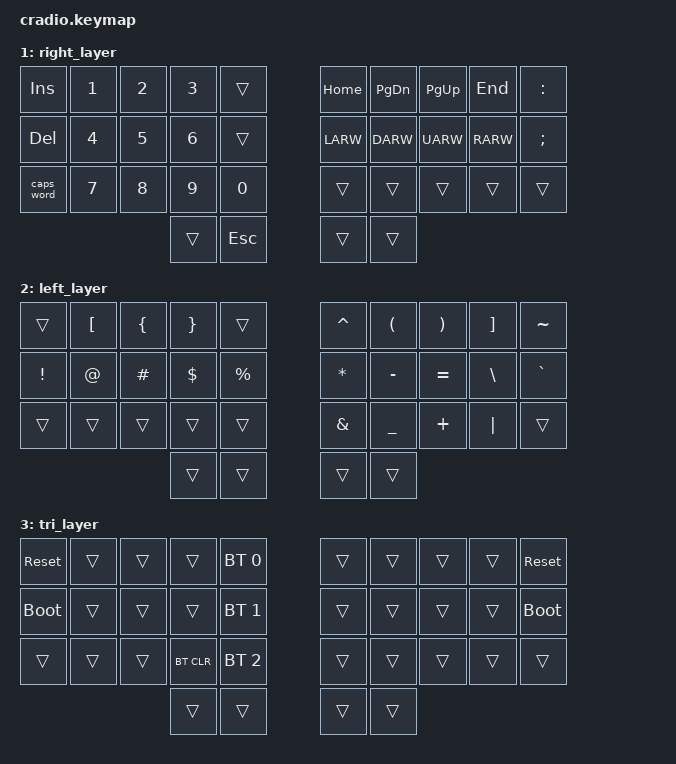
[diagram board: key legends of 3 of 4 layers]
// Copyright (c) 2022 The ZMK Contributors
// SPDX-License-Identifier: MIT

#include <behaviors.dtsi>
#include <dt-bindings/zmk/keys.h>
#include <dt-bindings/zmk/bt.h>

// Home row mods macro
#define HRML(k1,k2,k3,k4) &ht LSHFT k1  &ht LALT k2  &ht LCTRL k3  &ht LGUI k4
#define HRMR(k1,k2,k3,k4) &ht RGUI k1  &ht RCTRL k2  &ht RALT k3  &ht RSHFT k4
#include <dt-bindings/zmk/matrix_transform.h>

&default_transform {
    map = <
    RC(0,14) RC(0,1)  RC(0,2)  RC(0,3)  RC(0,4)    RC(0,21) RC(0,20) RC(0,19) RC(0,18) RC(0,31)
    RC(0,5)  RC(0,6)  RC(0,7)  RC(0,8)  RC(0,9)    RC(0,27) RC(0,26) RC(0,24) RC(0,23) RC(0,22)
    RC(0,10) RC(0,11) RC(0,12) RC(0,13) RC(0,0)    RC(0,32) RC(0,17) RC(0,30) RC(0,33) RC(0,28)
                               RC(0,16) RC(0,15)   RC(0,29) RC(0,25)
    >;
};
/ {
    behaviors {
        ht: hold_tap {
            label = "hold_tap";
            compatible = "zmk,behavior-hold-tap";
            #binding-cells = <2>;
            flavor = "tap-preferred";
            tapping-term-ms = <220>;
            quick-tap-ms = <150>;
            global-quick-tap;
            bindings = <&kp>, <&kp>;
        };
    };

    conditional_layers {
        compatible = "zmk,conditional-layers";
        tri_layer {
            if-layers = <1 2>;
            then-layer = <3>;
        };
    };

    keymap {
        compatible = "zmk,keymap";
        default_layer {
            bindings = <
        //╭──────────┬──────────┬──────────┬──────────┬──────────╮   ╭──────────┬──────────┬──────────┬──────────┬──────────╮
        //│  Q       │  W       │  E       │  R       │  T       │   │  Y       │  U       │  I       │  O       │  P       │
            &kp Q      &kp W      &kp E      &kp R      &kp T          &kp Y      &kp U      &kp I      &kp O      &kp P
        //├──────────┼──────────┼──────────┼──────────┼──────────┤   ├──────────┼──────────┼──────────┼──────────┼──────────┤
        //│  A       │  S       │  D       │  F       │  G       │   │  H       │  J       │  K       │  L       │ ' "      │
            HRML(A,        S,         D,         F)     &kp G          &kp H      HRMR(J,        K,         L,        SQT)
        //├──────────┼──────────┼──────────┼──────────┼──────────┤   ├──────────┼──────────┼──────────┼──────────┼──────────┤
        //│  Z       │  X       │  C       │  V       │  B       │   │  N       │  M       │ , <      │ . >      │ / ?      │
            &kp Z      &kp X      &kp C      &kp V      &kp B          &kp N      &kp M      &kp COMMA  &kp DOT    &kp FSLH
        //╰──────────┴──────────┴──────────┼──────────┼──────────┤   ├──────────┼──────────┼──────────┴──────────┴──────────╯
                                            &lt 2 TAB   &kp SPACE     &kp BCPC  &lt 1 ENTER
        //                                 ╰──────────┴──────────╯   ╰──────────┴──────────╯
            >;
        };

        right_layer {
            bindings = <
        //╭──────────┬──────────┬──────────┬──────────┬──────────╮   ╭──────────┬──────────┬──────────┬──────────┬──────────╮
        //│ INSERT   │  1       │  2       │  3       │          │   │ HOME     │ PAGE DN  │ PAGE UP  │ END      │  :       │
            &kp INS    &kp N1     &kp N2     &kp N3     &trans         &kp HOME   &kp PG_DN  &kp PG_UP  &kp END    &kp COLON
        //├──────────┼──────────┼──────────┼──────────┼──────────┤   ├──────────┼──────────┼──────────┼──────────┼──────────┤
        //│ DELETE   │  4       │  5       │  6       │          │   │ LEFT     │ DOWN     │ UP       │ RIGHT    │  ;       │
            &kp DEL    &kp N4     &kp N5     &kp N6     &trans         &kp LARW   &kp DARW   &kp UARW   &kp RARW   &kp SEMI
        //├──────────┼──────────┼──────────┼──────────┼──────────┤   ├──────────┼──────────┼──────────┼──────────┼──────────┤
        //│ CAPS     │  7       │  8       │  9       │  0       │   │          │          │          │          │          │
           &caps_word  &kp N7     &kp N8     &kp N9     &kp N0         &trans     &trans     &trans     &trans     &trans
        //╰──────────┴──────────┴──────────┼──────────┼──────────┤   ├──────────┼──────────┼──────────┴──────────┴──────────╯
                                             &trans     &kp ESC        &trans     &trans
        //                                 ╰──────────┴──────────╯   ╰──────────┴──────────╯
            >;
        };

        left_layer {
            bindings = <
        //╭──────────┬──────────┬──────────┬──────────┬──────────╮   ╭──────────┬──────────┬──────────┬──────────┬──────────╮
        //│          │  [       │  {       │  }       │          │   │  ^       │  (       │  )       │  ]       │  ~       │
            &trans     &kp LBKT   &kp LBRC   &kp RBRC   &trans         &kp CARET  &kp LPAR   &kp RPAR   &kp RBKT   &kp TILDE
        //├──────────┼──────────┼──────────┼──────────┼──────────┤   ├──────────┼──────────┼──────────┼──────────┼──────────┤
        //│  !       │  @       │  #       │  $       │  %       │   │  *       │  -       │  =       │  \       │  `       │
            &kp EXCL   &kp AT     &kp HASH   &kp DLLR   &kp PRCNT      &kp ASTRK  &kp MINUS  &kp EQUAL  &kp BSLH   &kp GRAVE
        //├──────────┼──────────┼──────────┼──────────┼──────────┤   ├──────────┼──────────┼──────────┼──────────┼──────────┤
        //│          │          │          │          │          │   │  &       │  _       │  +       │  │       │          │
            &trans     &trans     &trans     &trans     &trans         &kp AMPS   &kp UNDER  &kp PLUS   &kp PIPE   &trans
        //╰──────────┴──────────┴──────────┼──────────┼──────────┤   ├──────────┼──────────┼──────────┴──────────┴──────────╯
                                             &trans     &trans         &trans     &trans
        //                                 ╰──────────┴──────────╯   ╰──────────┴──────────╯
            >;
        };

        tri_layer {
            bindings = <
        //╭──────────┬──────────┬──────────┬──────────┬──────────╮   ╭──────────┬──────────┬──────────┬──────────┬──────────╮
        //│ RESET    │          │          │          │PROFILE 0 │   │          │          │          │          │  RESET   │
           &sys_reset  &trans     &trans     &trans    &bt BT_SEL 0    &trans     &trans     &trans     &trans    &sys_reset
        //├──────────┼──────────┼──────────┼──────────┼──────────┤   ├──────────┼──────────┼──────────┼──────────┼──────────┤
        //│BOOTLOADER│          │          │          │PROFILE 1 │   │          │          │          │          │BOOTLOADER│
          &bootloader  &trans     &trans     &trans    &bt BT_SEL 1    &trans     &trans     &trans     &trans    &bootloader
        //├──────────┼──────────┼──────────┼──────────┼──────────┤   ├──────────┼──────────┼──────────┼──────────┼──────────┤
        //│          │          │          │ CLEAR BT │PROFILE 2 │   │          │          │          │          │          │
            &trans     &trans     &trans    &bt BT_CLR &bt BT_SEL 2    &trans     &trans     &trans     &trans     &trans
        //╰──────────┴──────────┴──────────┼──────────┼──────────┤   ├──────────┼──────────┼──────────┴──────────┴──────────╯
                                             &trans     &trans         &trans     &trans
        //                                 ╰──────────┴──────────╯   ╰──────────┴──────────╯
            >;
        };
    };
};
